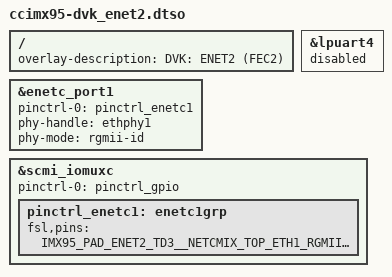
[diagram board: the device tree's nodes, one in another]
// SPDX-License-Identifier: (GPL-2.0+ OR MIT)
/*
 * Copyright 2025 Digi International Inc.
 */

/dts-v1/;
/plugin/;
#include "../freescale/imx95-pinfunc.h"

/ {
	fragment@0 {
		target-path = "/";
		__overlay__ {
			overlay-description = "DVK: ENET2 (FEC2)";
		};
	};

	/* Enable FEC2 interface */
	fragment@1 {
		target = <&enetc_port1>;
		__overlay__ {
			pinctrl-names = "default";
			pinctrl-0 = <&pinctrl_enetc1>;
			phy-handle = <&ethphy1>;
			phy-mode = "rgmii-id";
			status = "okay";
		};
	};

	/* Disable the uart of the XBee interface */
	fragment@2 {
		target = <&lpuart4>;
		__overlay__ {
			status = "disabled";
		};
	};

	fragment@3 {
		target = <&scmi_iomuxc>;
		__overlay__ {
			/* Remove shared ENET2 GPIOs */
			pinctrl-0 = <&pinctrl_gpio>;

			pinctrl_enetc1: enetc1grp {
				fsl,pins = <
					IMX95_PAD_ENET2_TD3__NETCMIX_TOP_ETH1_RGMII_TD3		0x57e
					IMX95_PAD_ENET2_TD2__NETCMIX_TOP_ETH1_RGMII_TD2		0x57e
					IMX95_PAD_ENET2_TD1__NETCMIX_TOP_ETH1_RGMII_TD1		0x57e
					IMX95_PAD_ENET2_TD0__NETCMIX_TOP_ETH1_RGMII_TD0		0x57e
					IMX95_PAD_ENET2_TX_CTL__NETCMIX_TOP_ETH1_RGMII_TX_CTL	0x58e
					IMX95_PAD_ENET2_TXC__NETCMIX_TOP_ETH1_RGMII_TX_CLK	0x5fe
					IMX95_PAD_ENET2_RX_CTL__NETCMIX_TOP_ETH1_RGMII_RX_CTL	0x58e
					IMX95_PAD_ENET2_RXC__NETCMIX_TOP_ETH1_RGMII_RX_CLK	0x5fe
					IMX95_PAD_ENET2_RD0__NETCMIX_TOP_ETH1_RGMII_RD0		0x57e
					IMX95_PAD_ENET2_RD1__NETCMIX_TOP_ETH1_RGMII_RD1		0x57e
					IMX95_PAD_ENET2_RD2__NETCMIX_TOP_ETH1_RGMII_RD2		0x57e
					IMX95_PAD_ENET2_RD3__NETCMIX_TOP_ETH1_RGMII_RD3		0x57e
				>;
			};
		};
	};
};
